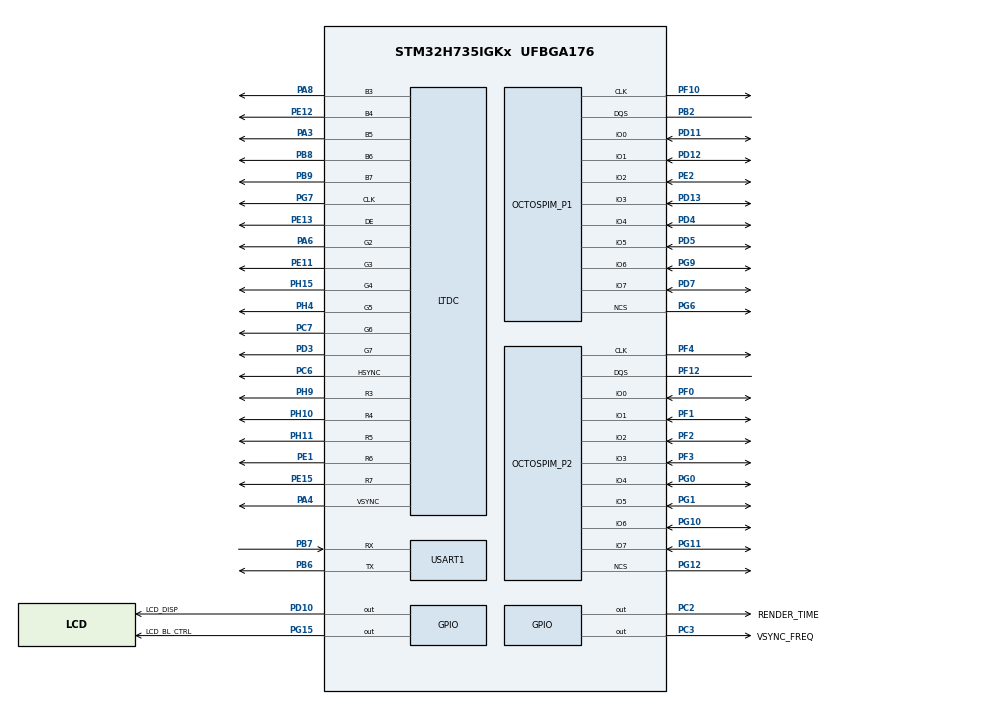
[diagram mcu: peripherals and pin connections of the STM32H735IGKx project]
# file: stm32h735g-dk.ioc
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CORTEX_M7.AccessPermission-Cortex_Memory_Protection_Unit_Region0_Settings=MPU_REGION_FULL_ACCESS
CORTEX_M7.AccessPermission-Cortex_Memory_Protection_Unit_Region2_Settings=MPU_REGION_FULL_ACCESS
CORTEX_M7.AccessPermission-Cortex_Memory_Protection_Unit_Region4_Settings=MPU_REGION_FULL_ACCESS
CORTEX_M7.BaseAddress-Cortex_Memory_Protection_Unit_Region0_Settings=0x24000000
CORTEX_M7.BaseAddress-Cortex_Memory_Protection_Unit_Region1_Settings=0x70000000
CORTEX_M7.BaseAddress-Cortex_Memory_Protection_Unit_Region2_Settings=0x70000000
CORTEX_M7.BaseAddress-Cortex_Memory_Protection_Unit_Region3_Settings=0x90000000
CORTEX_M7.BaseAddress-Cortex_Memory_Protection_Unit_Region4_Settings=0x90000000
CORTEX_M7.CPU_DCache=Enabled
CORTEX_M7.CPU_ICache=Enabled
CORTEX_M7.DisableExec-Cortex_Memory_Protection_Unit_Region0_Settings=MPU_INSTRUCTION_ACCESS_DISABLE
CORTEX_M7.DisableExec-Cortex_Memory_Protection_Unit_Region1_Settings=MPU_INSTRUCTION_ACCESS_DISABLE
CORTEX_M7.DisableExec-Cortex_Memory_Protection_Unit_Region2_Settings=MPU_INSTRUCTION_ACCESS_DISABLE
CORTEX_M7.DisableExec-Cortex_Memory_Protection_Unit_Region3_Settings=MPU_INSTRUCTION_ACCESS_DISABLE
CORTEX_M7.DisableExec-Cortex_Memory_Protection_Unit_Region4_Settings=MPU_INSTRUCTION_ACCESS_DISABLE
CORTEX_M7.Enable-Cortex_Memory_Protection_Unit_Region0_Settings=MPU_REGION_ENABLE
CORTEX_M7.Enable-Cortex_Memory_Protection_Unit_Region1_Settings=MPU_REGION_ENABLE
CORTEX_M7.Enable-Cortex_Memory_Protection_Unit_Region2_Settings=MPU_REGION_ENABLE
CORTEX_M7.Enable-Cortex_Memory_Protection_Unit_Region3_Settings=MPU_REGION_ENABLE
CORTEX_M7.Enable-Cortex_Memory_Protection_Unit_Region4_Settings=MPU_REGION_ENABLE
CORTEX_M7.IsBufferable-Cortex_Memory_Protection_Unit_Region0_Settings=MPU_ACCESS_BUFFERABLE
CORTEX_M7.IsBufferable-Cortex_Memory_Protection_Unit_Region2_Settings=MPU_ACCESS_NOT_BUFFERABLE
CORTEX_M7.IsCacheable-Cortex_Memory_Protection_Unit_Region0_Settings=MPU_ACCESS_CACHEABLE
CORTEX_M7.IsCacheable-Cortex_Memory_Protection_Unit_Region2_Settings=MPU_ACCESS_CACHEABLE
CORTEX_M7.IsCacheable-Cortex_Memory_Protection_Unit_Region4_Settings=MPU_ACCESS_CACHEABLE
CORTEX_M7.MPU_Control=MPU_PRIVILEGED_DEFAULT
CORTEX_M7.Size-Cortex_Memory_Protection_Unit_Region0_Settings=MPU_REGION_SIZE_512KB
CORTEX_M7.Size-Cortex_Memory_Protection_Unit_Region1_Settings=MPU_REGION_SIZE_512MB
CORTEX_M7.Size-Cortex_Memory_Protection_Unit_Region2_Settings=MPU_REGION_SIZE_8MB
CORTEX_M7.Size-Cortex_Memory_Protection_Unit_Region3_Settings=MPU_REGION_SIZE_512MB
CORTEX_M7.Size-Cortex_Memory_Protection_Unit_Region4_Settings=MPU_REGION_SIZE_64MB
DMA2D.ColorMode=DMA2D_OUTPUT_RGB888
DMA2D.Mode=DMA2D_R2M
Mcu.Family=STM32H7
Mcu.Name=STM32H735IGKx
Mcu.Package=UFBGA176
NVIC.LTDC_IRQn=true\:0\:0\:false\:true\:true\:1\:true\:false\:true
NVIC.PriorityGroup=NVIC_PRIORITYGROUP_4
NVIC.TIM6_DAC_IRQn=true\:15\:0\:false\:false\:true\:false\:true\:true
NVIC.TimeBase=TIM6_DAC_IRQn
NVIC.TimeBaseIP=TIM6
OCTOSPI1.ChipSelectBoundary=0
OCTOSPI1.ChipSelectHighTime=2
OCTOSPI1.ClockPrescaler=2
OCTOSPI1.FifoThreshold=4
OCTOSPI1.MemoryType=HAL_OSPI_MEMTYPE_MACRONIX
OCTOSPI2.AccessTime=6
OCTOSPI2.ChipSelectBoundary=23
OCTOSPI2.ChipSelectHighTime=4
OCTOSPI2.ClkChipSelectHighTime=0
OCTOSPI2.ClockPrescaler=2
OCTOSPI2.DelayBlockBypass=HAL_OSPI_DELAY_BLOCK_USED
OCTOSPI2.DelayHoldQuarterCycle=HAL_OSPI_DHQC_ENABLE
OCTOSPI2.DeviceSize=24
OCTOSPI2.FifoThreshold=4
OCTOSPI2.LatencyMode=HAL_OSPI_FIXED_LATENCY
OCTOSPI2.RWRecoveryTime=3
OCTOSPI2.Refresh=400
OCTOSPI2.WriteZeroLatency=HAL_OSPI_LATENCY_ON_WRITE
PA3.GPIO_Speed=GPIO_SPEED_FREQ_VERY_HIGH
PA3.Mode=RGB565
PA3.Signal=LTDC_B5
PA4.GPIO_Speed=GPIO_SPEED_FREQ_VERY_HIGH
PA4.Mode=RGB565
PA4.Signal=LTDC_VSYNC
PA6.GPIO_Speed=GPIO_SPEED_FREQ_VERY_HIGH
PA6.Mode=RGB565
PA6.Signal=LTDC_G2
PA8.GPIO_Speed=GPIO_SPEED_FREQ_VERY_HIGH
PA8.Mode=RGB565
PA8.Signal=LTDC_B3
PB0.GPIO_Speed=GPIO_SPEED_FREQ_VERY_HIGH
PB0.Signal=LTDC_G1
PB1.GPIO_Speed=GPIO_SPEED_FREQ_VERY_HIGH
PB1.Signal=LTDC_G0
PB2.Mode=OCTOSPI1_Port1_DQS
PB2.Signal=OCTOSPIM_P1_DQS
PB6.Mode=Asynchronous
PB6.Signal=USART1_TX
PB7.Mode=Asynchronous
PB7.Signal=USART1_RX
PB8.Mode=RGB565
PB8.Signal=LTDC_B6
PB9.Mode=RGB565
PB9.Signal=LTDC_B7
PC2.GPIO_Label=RENDER_TIME
PC2.GPIO_PuPd=GPIO_PULLUP
PC2.GPIO_Speed=GPIO_SPEED_FREQ_VERY_HIGH
PC2.PinState=GPIO_PIN_SET
PC2.Signal=GPIO_Output
PC3.GPIO_Label=VSYNC_FREQ
PC3.GPIO_PuPd=GPIO_PULLUP
PC3.GPIO_Speed=GPIO_SPEED_FREQ_VERY_HIGH
PC3.PinState=GPIO_PIN_SET
PC3.Signal=GPIO_Output
PC6.Mode=RGB565
PC6.Signal=LTDC_HSYNC
PC7.Mode=RGB565
PC7.Signal=LTDC_G6
PD10.GPIO_Label=LCD_DISP
PD10.GPIO_PuPd=GPIO_NOPULL
PD10.GPIO_Speed=GPIO_SPEED_FREQ_LOW
PD10.PinState=GPIO_PIN_RESET
PD10.Signal=GPIO_Output
PD11.Mode=OCTOSPI1_IOL_Port1L
PD11.Signal=OCTOSPIM_P1_IO0
PD12.Mode=OCTOSPI1_IOL_Port1L
PD12.Signal=OCTOSPIM_P1_IO1
PD13.Mode=OCTOSPI1_IOL_Port1L
PD13.Signal=OCTOSPIM_P1_IO3
PD3.Mode=RGB565
PD3.Signal=LTDC_G7
PD4.Mode=OCTOSPI1_IOH_Port1H
PD4.Signal=OCTOSPIM_P1_IO4
PD5.Mode=OCTOSPI1_IOH_Port1H
PD5.Signal=OCTOSPIM_P1_IO5
PD6.GPIO_Speed=GPIO_SPEED_FREQ_VERY_HIGH
PD6.Signal=LTDC_B2
PD7.Mode=OCTOSPI1_IOH_Port1H
PD7.Signal=OCTOSPIM_P1_IO7
PE1.GPIO_Speed=GPIO_SPEED_FREQ_VERY_HIGH
PE1.Mode=RGB565
PE1.Signal=LTDC_R6
PE11.GPIO_Speed=GPIO_SPEED_FREQ_VERY_HIGH
PE11.Mode=RGB565
PE11.Signal=LTDC_G3
PE12.GPIO_Speed=GPIO_SPEED_FREQ_VERY_HIGH
PE12.Mode=RGB565
PE12.Signal=LTDC_B4
PE13.GPIO_Speed=GPIO_SPEED_FREQ_VERY_HIGH
PE13.Mode=RGB565
PE13.Signal=LTDC_DE
PE15.GPIO_Speed=GPIO_SPEED_FREQ_VERY_HIGH
PE15.Mode=RGB565
PE15.Signal=LTDC_R7
PE2.Mode=OCTOSPI1_IOL_Port1L
PE2.Signal=OCTOSPIM_P1_IO2
PF0.Mode=OCTOSPI2_IOL_Port2L
PF0.Signal=OCTOSPIM_P2_IO0
PF1.Mode=OCTOSPI2_IOL_Port2L
PF1.Signal=OCTOSPIM_P2_IO1
PF10.Mode=O1_P1_CLK
PF10.Signal=OCTOSPIM_P1_CLK
PF12.Mode=OCTOSPI2_Port2_DQS
PF12.Signal=OCTOSPIM_P2_DQS
PF2.Mode=OCTOSPI2_IOL_Port2L
PF2.Signal=OCTOSPIM_P2_IO2
PF3.Mode=OCTOSPI2_IOL_Port2L
PF3.Signal=OCTOSPIM_P2_IO3
PF4.Mode=O2_P2_CLK
PF4.Signal=OCTOSPIM_P2_CLK
PG0.Mode=OCTOSPI2_IOH_Port2H
PG0.Signal=OCTOSPIM_P2_IO4
PG1.Mode=OCTOSPI2_IOH_Port2H
PG1.Signal=OCTOSPIM_P2_IO5
PG10.Mode=OCTOSPI2_IOH_Port2H
PG10.Signal=OCTOSPIM_P2_IO6
PG11.Mode=OCTOSPI2_IOH_Port2H
PG11.Signal=OCTOSPIM_P2_IO7
PG12.Mode=OCTOSPI2_Port2_NCS
PG12.Signal=OCTOSPIM_P2_NCS
PG14.GPIO_Speed=GPIO_SPEED_FREQ_VERY_HIGH
PG14.Signal=LTDC_B0
PG15.GPIO_Label=LCD_BL_CTRL
PG15.Signal=GPIO_Output
PG6.Mode=OCTOSPI1_Port1_NCS
PG6.Signal=OCTOSPIM_P1_NCS
PG7.Mode=RGB565
PG7.Signal=LTDC_CLK
PG9.Mode=OCTOSPI1_IOH_Port1H
PG9.Signal=OCTOSPIM_P1_IO6
PH0-OSC_IN.Mode=HSE-External-Oscillator
PH0-OSC_IN.Signal=RCC_OSC_IN
PH1-OSC_OUT.Mode=HSE-External-Oscillator
PH1-OSC_OUT.Signal=RCC_OSC_OUT
PH10.GPIO_Speed=GPIO_SPEED_FREQ_VERY_HIGH
PH10.Mode=RGB565
PH10.Signal=LTDC_R4
PH11.GPIO_Speed=GPIO_SPEED_FREQ_VERY_HIGH
PH11.Mode=RGB565
PH11.Signal=LTDC_R5
PH15.Mode=RGB565
PH15.Signal=LTDC_G4
PH3.GPIO_Speed=GPIO_SPEED_FREQ_VERY_HIGH
PH3.Signal=LTDC_R1
PH4.GPIO_Speed=GPIO_SPEED_FREQ_VERY_HIGH
PH4.Mode=RGB565
PH4.Signal=LTDC_G5
PH8.GPIO_Speed=GPIO_SPEED_FREQ_VERY_HIGH
PH8.Signal=LTDC_R2
PH9.GPIO_Speed=GPIO_SPEED_FREQ_VERY_HIGH
PH9.Mode=RGB565
PH9.Signal=LTDC_R3
ProjectManager.HeapSize=0x1000
ProjectManager.StackSize=0x1000
ProjectManager.TargetToolchain=CMake
RCC.ADCFreq_Value=200000000
RCC.APB1Freq_Value=137500000
RCC.APB2Freq_Value=137500000
RCC.APB3Freq_Value=137500000
RCC.APB4Freq_Value=137500000
RCC.CortexFreq_Value=550000000
RCC.D1PPRE=RCC_APB3_DIV2
RCC.D2PPRE1=RCC_APB1_DIV2
RCC.D2PPRE2=RCC_APB2_DIV2
RCC.D3PPRE=RCC_APB4_DIV2
RCC.DIVM1=2
RCC.DIVM2=5
RCC.DIVM3=25
RCC.DIVN1=44
RCC.DIVN2=80
RCC.DIVN3=288
RCC.DIVP1=1
RCC.DIVR3=30
RCC.HCLKFreq_Value=275000000
RCC.HPRE=RCC_HCLK_DIV2
RCC.PLL2FRACN=0
RCC.PLL3FRACN=0
RCC.PLLFRACN=0
RCC.PLLSourceVirtual=RCC_PLLSOURCE_HSE
RCC.QSPICLockSelection=RCC_OSPICLKSOURCE_PLL2
RCC.SYSCLKFreq_VALUE=550000000
RCC.SYSCLKSource=RCC_SYSCLKSOURCE_PLLCLK
RCC.SupplySource=PWR_DIRECT_SMPS_SUPPLY
RCC.USBFreq_Value=275000000
USART1.VirtualMode-Asynchronous=VM_ASYNC
VP_CRC_VS_CRC.Mode=CRC_Activate
VP_DMA2D_VS_DMA2D.Mode=DMA2D_Activate
VP_MEMORYMAP_VS_MEMORYMAP.Mode=CurAppReg
VP_OCTOSPI1_VS_octo.Mode=octo_mode
VP_OCTOSPI2_VS_octo.Mode=hyperbus_mode
VP_SYS_VS_tim6.Mode=TIM6
board=custom

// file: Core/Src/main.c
/* USER CODE BEGIN Header */
/**
  ******************************************************************************
  * @file           : main.c
  * @brief          : Main program body
  ******************************************************************************
  * @attention
  *
  * Copyright (c) 2024 STMicroelectronics.
  * All rights reserved.
  *
  * This software is licensed under terms that can be found in the LICENSE file
  * in the root directory of this software component.
  * If no LICENSE file comes with this software, it is provided AS-IS.
  *
  ******************************************************************************
  */
/* USER CODE END Header */
#include "main.h"

UART_HandleTypeDef huart1;

void SystemClock_Config(void);
void PeriphCommonClock_Config(void);
static void MPU_Config(void);
static void MX_GPIO_Init(void);
static void MX_USART1_UART_Init(void);
static void MX_NVIC_Init(void);
/* USER CODE BEGIN PFP */
int appmain(void);
/* USER CODE END PFP */

int main(void)
{

  /* MPU Configuration--------------------------------------------------------*/
  MPU_Config();

  /* Enable the CPU Cache */

  /* Enable I-Cache---------------------------------------------------------*/
  SCB_EnableICache();

  /* Enable D-Cache---------------------------------------------------------*/
  SCB_EnableDCache();

  /* MCU Configuration--------------------------------------------------------*/

  /* Reset of all peripherals, Initializes the Flash interface and the Systick. */
  HAL_Init();

  /* Configure the system clock */
  SystemClock_Config();

  /* Configure the peripherals common clocks */
  PeriphCommonClock_Config();

  /* Initialize all configured peripherals */
  MX_GPIO_Init();
  MX_USART1_UART_Init();

  /* Initialize interrupts */
  MX_NVIC_Init();
  /* USER CODE BEGIN 2 */
  appmain();
  /* USER CODE END 2 */

  /* Infinite loop */
  while (1)
  {

  }
}

void SystemClock_Config(void)
{
  RCC_OscInitTypeDef RCC_OscInitStruct = {0};
  RCC_ClkInitTypeDef RCC_ClkInitStruct = {0};

  /** Supply configuration update enable
  */
  HAL_PWREx_ConfigSupply(PWR_DIRECT_SMPS_SUPPLY);

  /** Configure the main internal regulator output voltage
  */
  __HAL_PWR_VOLTAGESCALING_CONFIG(PWR_REGULATOR_VOLTAGE_SCALE0);

  while(!__HAL_PWR_GET_FLAG(PWR_FLAG_VOSRDY)) {}

  /** Initializes the RCC Oscillators according to the specified parameters
  * in the RCC_OscInitTypeDef structure.
  */
  RCC_OscInitStruct.OscillatorType = RCC_OSCILLATORTYPE_HSE;
  RCC_OscInitStruct.HSEState = RCC_HSE_ON;
  RCC_OscInitStruct.PLL.PLLState = RCC_PLL_ON;
  RCC_OscInitStruct.PLL.PLLSource = RCC_PLLSOURCE_HSE;
  RCC_OscInitStruct.PLL.PLLM = 2;
  RCC_OscInitStruct.PLL.PLLN = 44;
  RCC_OscInitStruct.PLL.PLLP = 1;
  RCC_OscInitStruct.PLL.PLLQ = 2;
  RCC_OscInitStruct.PLL.PLLR = 2;
  RCC_OscInitStruct.PLL.PLLRGE = RCC_PLL1VCIRANGE_3;
  RCC_OscInitStruct.PLL.PLLVCOSEL = RCC_PLL1VCOWIDE;
  RCC_OscInitStruct.PLL.PLLFRACN = 0;
  if (HAL_RCC_OscConfig(&RCC_OscInitStruct) != HAL_OK)
  {
    Error_Handler();
  }

  /** Initializes the CPU, AHB and APB buses clocks
  */
  RCC_ClkInitStruct.ClockType = RCC_CLOCKTYPE_HCLK|RCC_CLOCKTYPE_SYSCLK
                              |RCC_CLOCKTYPE_PCLK1|RCC_CLOCKTYPE_PCLK2
                              |RCC_CLOCKTYPE_D3PCLK1|RCC_CLOCKTYPE_D1PCLK1;
  RCC_ClkInitStruct.SYSCLKSource = RCC_SYSCLKSOURCE_PLLCLK;
  RCC_ClkInitStruct.SYSCLKDivider = RCC_SYSCLK_DIV1;
  RCC_ClkInitStruct.AHBCLKDivider = RCC_HCLK_DIV2;
  RCC_ClkInitStruct.APB3CLKDivider = RCC_APB3_DIV2;
  RCC_ClkInitStruct.APB1CLKDivider = RCC_APB1_DIV2;
  RCC_ClkInitStruct.APB2CLKDivider = RCC_APB2_DIV2;
  RCC_ClkInitStruct.APB4CLKDivider = RCC_APB4_DIV2;

  if (HAL_RCC_ClockConfig(&RCC_ClkInitStruct, FLASH_LATENCY_3) != HAL_OK)
  {
    Error_Handler();
  }
}

void PeriphCommonClock_Config(void)
{
  RCC_PeriphCLKInitTypeDef PeriphClkInitStruct = {0};

  /** Initializes the peripherals clock
  */
  PeriphClkInitStruct.PeriphClockSelection = RCC_PERIPHCLK_OSPI;
  PeriphClkInitStruct.PLL2.PLL2M = 5;
  PeriphClkInitStruct.PLL2.PLL2N = 80;
  PeriphClkInitStruct.PLL2.PLL2P = 2;
  PeriphClkInitStruct.PLL2.PLL2Q = 2;
  PeriphClkInitStruct.PLL2.PLL2R = 2;
  PeriphClkInitStruct.PLL2.PLL2RGE = RCC_PLL2VCIRANGE_2;
  PeriphClkInitStruct.PLL2.PLL2VCOSEL = RCC_PLL2VCOWIDE;
  PeriphClkInitStruct.PLL2.PLL2FRACN = 0;
  PeriphClkInitStruct.OspiClockSelection = RCC_OSPICLKSOURCE_PLL2;
  if (HAL_RCCEx_PeriphCLKConfig(&PeriphClkInitStruct) != HAL_OK)
  {
    Error_Handler();
  }
}

/**
  * @brief NVIC Configuration.
  * @retval None
  */
static void MX_NVIC_Init(void)
{
  /* LTDC_IRQn interrupt configuration */
  HAL_NVIC_SetPriority(LTDC_IRQn, 0, 0);
  HAL_NVIC_EnableIRQ(LTDC_IRQn);
}

static void MX_USART1_UART_Init(void)
{

  huart1.Instance = USART1;
  huart1.Init.BaudRate = 115200;
  huart1.Init.WordLength = UART_WORDLENGTH_8B;
  huart1.Init.StopBits = UART_STOPBITS_1;
  huart1.Init.Parity = UART_PARITY_NONE;
  huart1.Init.Mode = UART_MODE_TX_RX;
  huart1.Init.HwFlowCtl = UART_HWCONTROL_NONE;
  huart1.Init.OverSampling = UART_OVERSAMPLING_16;
  huart1.Init.OneBitSampling = UART_ONE_BIT_SAMPLE_DISABLE;
  huart1.Init.ClockPrescaler = UART_PRESCALER_DIV1;
  huart1.AdvancedInit.AdvFeatureInit = UART_ADVFEATURE_NO_INIT;
  if (HAL_UART_Init(&huart1) != HAL_OK)
  {
    Error_Handler();
  }
  if (HAL_UARTEx_SetTxFifoThreshold(&huart1, UART_TXFIFO_THRESHOLD_1_8) != HAL_OK)
  {
    Error_Handler();
  }
  if (HAL_UARTEx_SetRxFifoThreshold(&huart1, UART_RXFIFO_THRESHOLD_1_8) != HAL_OK)
  {
    Error_Handler();
  }
  if (HAL_UARTEx_DisableFifoMode(&huart1) != HAL_OK)
  {
    Error_Handler();
  }

}

static void MX_GPIO_Init(void)
{
  GPIO_InitTypeDef GPIO_InitStruct = {0};

  /* GPIO Ports Clock Enable */
  __HAL_RCC_GPIOB_CLK_ENABLE();
  __HAL_RCC_GPIOG_CLK_ENABLE();
  __HAL_RCC_GPIOD_CLK_ENABLE();
  __HAL_RCC_GPIOA_CLK_ENABLE();
  __HAL_RCC_GPIOE_CLK_ENABLE();
  __HAL_RCC_GPIOH_CLK_ENABLE();
  __HAL_RCC_GPIOC_CLK_ENABLE();
  __HAL_RCC_GPIOF_CLK_ENABLE();

  /*Configure GPIO pin Output Level */
  HAL_GPIO_WritePin(LCD_BL_CTRL_GPIO_Port, LCD_BL_CTRL_Pin, GPIO_PIN_RESET);

  /*Configure GPIO pin Output Level */
  HAL_GPIO_WritePin(LCD_DISP_GPIO_Port, LCD_DISP_Pin, GPIO_PIN_RESET);

  /*Configure GPIO pin Output Level */
  HAL_GPIO_WritePin(GPIOC, RENDER_TIME_Pin|VSYNC_FREQ_Pin, GPIO_PIN_SET);

  /*Configure GPIO pin : LCD_BL_CTRL_Pin */
  GPIO_InitStruct.Pin = LCD_BL_CTRL_Pin;
  GPIO_InitStruct.Mode = GPIO_MODE_OUTPUT_PP;
  GPIO_InitStruct.Pull = GPIO_NOPULL;
  GPIO_InitStruct.Speed = GPIO_SPEED_FREQ_LOW;
  HAL_GPIO_Init(LCD_BL_CTRL_GPIO_Port, &GPIO_InitStruct);

  /*Configure GPIO pin : LCD_DISP_Pin */
  GPIO_InitStruct.Pin = LCD_DISP_Pin;
  GPIO_InitStruct.Mode = GPIO_MODE_OUTPUT_PP;
  GPIO_InitStruct.Pull = GPIO_NOPULL;
  GPIO_InitStruct.Speed = GPIO_SPEED_FREQ_LOW;
  HAL_GPIO_Init(LCD_DISP_GPIO_Port, &GPIO_InitStruct);

  /*Configure GPIO pins : RENDER_TIME_Pin VSYNC_FREQ_Pin */
  GPIO_InitStruct.Pin = RENDER_TIME_Pin|VSYNC_FREQ_Pin;
  GPIO_InitStruct.Mode = GPIO_MODE_OUTPUT_PP;
  GPIO_InitStruct.Pull = GPIO_PULLUP;
  GPIO_InitStruct.Speed = GPIO_SPEED_FREQ_VERY_HIGH;
  HAL_GPIO_Init(GPIOC, &GPIO_InitStruct);

}

 /* MPU Configuration */

void MPU_Config(void)
{
  MPU_Region_InitTypeDef MPU_InitStruct = {0};

  /* Disables the MPU */
  HAL_MPU_Disable();

  /** Initializes and configures the Region and the memory to be protected
  */
  MPU_InitStruct.Enable = MPU_REGION_ENABLE;
  MPU_InitStruct.Number = MPU_REGION_NUMBER0;
  MPU_InitStruct.BaseAddress = 0x24000000;
  MPU_InitStruct.Size = MPU_REGION_SIZE_512KB;
  MPU_InitStruct.SubRegionDisable = 0x0;
  MPU_InitStruct.TypeExtField = MPU_TEX_LEVEL0;
  MPU_InitStruct.AccessPermission = MPU_REGION_FULL_ACCESS;
  MPU_InitStruct.DisableExec = MPU_INSTRUCTION_ACCESS_DISABLE;
  MPU_InitStruct.IsShareable = MPU_ACCESS_NOT_SHAREABLE;
  MPU_InitStruct.IsCacheable = MPU_ACCESS_CACHEABLE;
  MPU_InitStruct.IsBufferable = MPU_ACCESS_BUFFERABLE;

  HAL_MPU_ConfigRegion(&MPU_InitStruct);

  /** Initializes and configures the Region and the memory to be protected
  */
  MPU_InitStruct.Number = MPU_REGION_NUMBER1;
  MPU_InitStruct.BaseAddress = 0x70000000;
  MPU_InitStruct.Size = MPU_REGION_SIZE_512MB;
  MPU_InitStruct.AccessPermission = MPU_REGION_NO_ACCESS;
  MPU_InitStruct.IsCacheable = MPU_ACCESS_NOT_CACHEABLE;
  MPU_InitStruct.IsBufferable = MPU_ACCESS_NOT_BUFFERABLE;

  HAL_MPU_ConfigRegion(&MPU_InitStruct);

  /** Initializes and configures the Region and the memory to be protected
  */
  MPU_InitStruct.Number = MPU_REGION_NUMBER2;
  MPU_InitStruct.Size = MPU_REGION_SIZE_8MB;
  MPU_InitStruct.AccessPermission = MPU_REGION_FULL_ACCESS;
  MPU_InitStruct.IsCacheable = MPU_ACCESS_CACHEABLE;

  HAL_MPU_ConfigRegion(&MPU_InitStruct);

  /** Initializes and configures the Region and the memory to be protected
  */
  MPU_InitStruct.Number = MPU_REGION_NUMBER3;
  MPU_InitStruct.BaseAddress = 0x90000000;
  MPU_InitStruct.Size = MPU_REGION_SIZE_512MB;
  MPU_InitStruct.AccessPermission = MPU_REGION_NO_ACCESS;
  MPU_InitStruct.IsCacheable = MPU_ACCESS_NOT_CACHEABLE;

  HAL_MPU_ConfigRegion(&MPU_InitStruct);

  /** Initializes and configures the Region and the memory to be protected
  */
  MPU_InitStruct.Number = MPU_REGION_NUMBER4;
  MPU_InitStruct.Size = MPU_REGION_SIZE_64MB;
  MPU_InitStruct.AccessPermission = MPU_REGION_FULL_ACCESS;
  MPU_InitStruct.IsCacheable = MPU_ACCESS_CACHEABLE;

  HAL_MPU_ConfigRegion(&MPU_InitStruct);
  /* Enables the MPU */
  HAL_MPU_Enable(MPU_PRIVILEGED_DEFAULT);

}

void HAL_TIM_PeriodElapsedCallback(TIM_HandleTypeDef *htim)
{
  if (htim->Instance == TIM6) {
    HAL_IncTick();
  }
}

void Error_Handler(void)
{
  __disable_irq();
  while (1)
  {
  }
}
